AUTOSAR XML (schema 4-0-3)
package /ARPackage_0
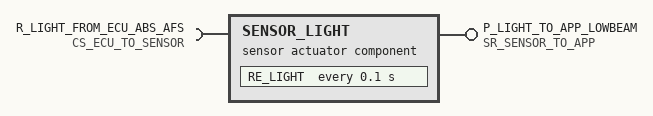
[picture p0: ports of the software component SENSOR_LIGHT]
  sensor actuator sw component type SENSOR_LIGHT
    provide port P_LIGHT_TO_APP_LOWBEAM: provided-interface=SR_SENSOR_TO_APP
    require port R_LIGHT_FROM_ECU_ABS_AFS: required-interface=CS_ECU_TO_SENSOR
    behavior IB_SENSOR_LIGHT
      timing event TE_LIGHT: start-on-event=RE_LIGHT, period=0.1
      runnable RE_LIGHT
        asynchronous server call result point AsynchronousServerCallResultPoint_0: asynchronous-server-call-point=AsynchronousServerCallPoint_0
        data-send-points:
          access DSP_VDP_SENSOR_TO_APP_0: accessed-variable=P_LIGHT_TO_APP_LOWBEAM.VDP_SENSOR_TO_APP
        async call AsynchronousServerCallPoint_0: operation=R_LIGHT_FROM_ECU_ABS_AFS.OPER_ECU_TO_SENSOR
